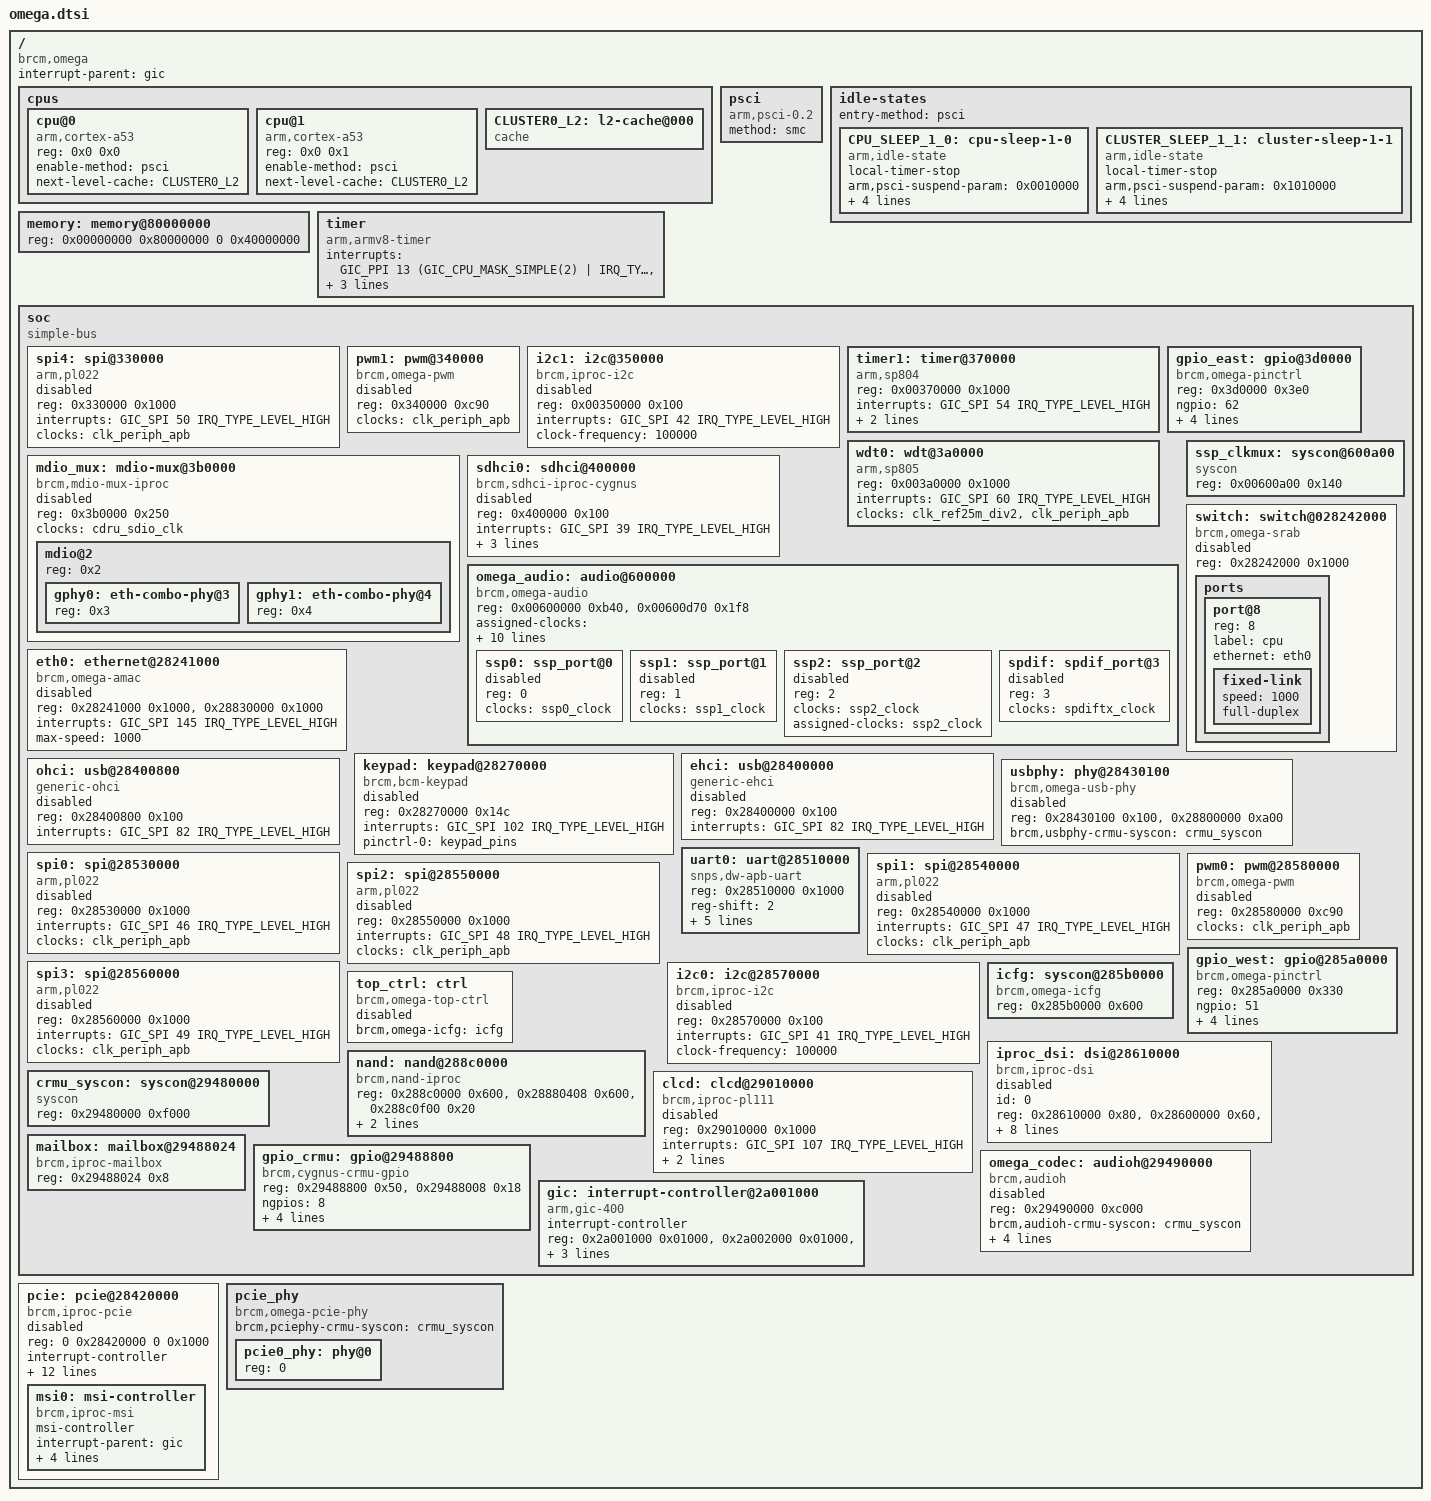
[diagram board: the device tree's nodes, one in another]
// SPDX-License-Identifier: (GPL-2.0 or BSD-3-Clause)
/*
 *  Copyright(c) 2018 Broadcom
 */

#include <dt-bindings/interrupt-controller/arm-gic.h>

/ {
	compatible = "brcm,omega";
	interrupt-parent = <&gic>;
	#address-cells = <2>;
	#size-cells = <2>;

	cpus {
		#address-cells = <2>;
		#size-cells = <0>;

		cpu@0 {
			device_type = "cpu";
			compatible = "arm,cortex-a53", "arm,armv8";
			reg = <0x0 0x0>;
			enable-method = "psci";
			next-level-cache = <&CLUSTER0_L2>;
		};

		cpu@1 {
			device_type = "cpu";
			compatible = "arm,cortex-a53", "arm,armv8";
			reg = <0x0 0x1>;
			enable-method = "psci";
			next-level-cache = <&CLUSTER0_L2>;
		};

		CLUSTER0_L2: l2-cache@000 {
			compatible = "cache";
		};

	};

	psci {
		compatible = "arm,psci-0.2";
		method = "smc";
	};

	idle-states {
		entry-method = "psci";
		CPU_SLEEP_1_0: cpu-sleep-1-0 {
			compatible = "arm,idle-state";
			local-timer-stop;
			arm,psci-suspend-param = <0x0010000>;
			entry-latency-us = <1>;
			exit-latency-us = <1>;
			min-residency-us = <900>;
			wakeup-latency-us = <1>;
		};

		CLUSTER_SLEEP_1_1: cluster-sleep-1-1 {
			compatible = "arm,idle-state";
			local-timer-stop;
			arm,psci-suspend-param = <0x1010000>;
			entry-latency-us = <1>;
			exit-latency-us = <1>;
			min-residency-us = <1800>;
			wakeup-latency-us = <1>;
		};
	};

	memory: memory@80000000 {
		device_type = "memory";
		reg = <0x00000000 0x80000000 0 0x40000000>;
	};

	timer {
		compatible = "arm,armv8-timer";
		interrupts = <GIC_PPI 13 (GIC_CPU_MASK_SIMPLE(2) |
			      IRQ_TYPE_LEVEL_LOW)>,
			     <GIC_PPI 14 (GIC_CPU_MASK_SIMPLE(2) |
			      IRQ_TYPE_LEVEL_LOW)>,
			     <GIC_PPI 11 (GIC_CPU_MASK_SIMPLE(2) |
			      IRQ_TYPE_LEVEL_LOW)>,
			     <GIC_PPI 10 (GIC_CPU_MASK_SIMPLE(2) |
			      IRQ_TYPE_LEVEL_LOW)>;
	};

	soc {
		compatible = "simple-bus";
		#address-cells = <1>;
		#size-cells = <1>;
		ranges = <0 0 0 0xffffffff>;

		#include "omega-clock.dtsi"
		#include "omega-pinctrl.dtsi"

		spi4: spi@330000 {
			compatible = "arm,pl022", "arm,primecell";
			reg = <0x330000 0x1000>;
			#address-cells = <1>;
			#size-cells = <0>;
			interrupts = <GIC_SPI 50 IRQ_TYPE_LEVEL_HIGH>;
			clocks = <&clk_periph_apb>;
			clock-names = "apb_pclk";
			status = "disabled";
		};

		pwm1: pwm@340000 {
			compatible = "brcm,omega-pwm";
			reg = <0x340000 0xc90>;
			clocks = <&clk_periph_apb>;
			#pwm-cells = <3>;
			status = "disabled";
		};

		i2c1: i2c@350000 {
			compatible = "brcm,iproc-i2c";
			reg = <0x00350000 0x100>;
			#address-cells = <1>;
			#size-cells = <0>;
			interrupts = <GIC_SPI 42 IRQ_TYPE_LEVEL_HIGH>;
			clock-frequency = <100000>;
			status = "disabled";
		};

		timer1: timer@370000 {
			compatible = "arm,sp804", "arm,primecell";
			reg = <0x00370000 0x1000>;
			interrupts = <GIC_SPI 54 IRQ_TYPE_LEVEL_HIGH>;
			clocks = <&clk_ref25m_div2>,
				 <&clk_ref25m_div2>,
				 <&clk_periph_apb>;
			clock-names = "timer1clk", "timer2clk", "apb_pclk";
		};

		wdt0: wdt@3a0000 {
			compatible = "arm,sp805", "arm,primecell";
			reg = <0x003a0000 0x1000>;
			interrupts = <GIC_SPI 60 IRQ_TYPE_LEVEL_HIGH>;
			clocks = <&clk_ref25m_div2>, <&clk_periph_apb>;
			clock-names = "wdogclk", "apb_pclk";
		};

		mdio_mux: mdio-mux@3b0000 {
			compatible = "brcm,mdio-mux-iproc";
			reg = <0x3b0000 0x250>;
			clocks = <&cdru_sdio_clk>;
			status = "disabled";
			#address-cells = <1>;
			#size-cells = <0>;

			mdio@2 {
				reg = <0x2>;
				#address-cells = <1>;
				#size-cells = <0>;

				gphy0: eth-combo-phy@3 {
					reg = <0x3>;
				};

				gphy1: eth-combo-phy@4 {
					reg = <0x4>;
				};
			};
		};

		gpio_east: gpio@3d0000 {
			compatible = "brcm,omega-pinctrl";
			reg = <0x3d0000 0x3e0>;
			ngpio = <62>;
			#gpio-cells = <2>;
			gpio-controller;
			interrupt-controller;
			#interrupt-cells = <3>;
			interrupts = <GIC_SPI 51 IRQ_TYPE_LEVEL_HIGH>;
			gpio-ranges = <&pinmux1 0 0 62>;
		};

		sdhci0: sdhci@400000 {
			compatible = "brcm,sdhci-iproc-cygnus";
			reg = <0x400000 0x100>;
			interrupts = <GIC_SPI 39 IRQ_TYPE_LEVEL_HIGH>;
			clocks = <&cdru_sdio_clk>;
			bus-width = <4>;
			sdhci,auto-cmd12;

			status = "disabled";
		};

		omega_audio: audio@600000 {
			compatible = "brcm,omega-audio";
			#address-cells = <1>;
			#size-cells = <0>;
			reg = <0x00600000 0xb40>, <0x00600d70 0x1f8>;
			reg-names = "aud", "i2s_in";

			assigned-clocks = <&audiopll_1 BCM_OMEGA_AUDIOPLL>,
					  <&ssp0_clock>,
					  <&ssp1_clock>,
					  <&ssp2_clock>,
					  <&spdiftx_clock>;
			assigned-clock-rates = <1376255989>;
			assigned-clock-parents = <0>,
					<&audiopll_1 BCM_OMEGA_AUDIOPLL_CH0>,
					<&audiopll_1 BCM_OMEGA_AUDIOPLL_CH1>,
					<&audiopll_1 BCM_OMEGA_AUDIOPLL_CH2>,
					<&audiopll_1 BCM_OMEGA_AUDIOPLL_CH3>;

			interrupts = <GIC_SPI 86 IRQ_TYPE_LEVEL_HIGH>; /* 143 */

			brcm,clk-mux-syscon = <&ssp_clkmux>;

			ssp0: ssp_port@0 {
				reg = <0>;
				clocks = <&ssp0_clock>;
				clock-names = "ssp_clk";
				status = "disabled";
			};

			ssp1: ssp_port@1 {
				reg = <1>;
				clocks = <&ssp1_clock>;
				clock-names = "ssp_clk";
				status = "disabled";
			};

			ssp2: ssp_port@2 {
				reg = <2>;
				clocks = <&ssp2_clock>;
				clock-names = "ssp_clk";
				assigned-clocks = <&ssp2_clock>;
				status = "disabled";
			};

			spdif: spdif_port@3 {
				reg = <3>;
				clocks = <&spdiftx_clock>;
				clock-names = "ssp_clk";
				status = "disabled";
			};
		};

		ssp_clkmux: syscon@600a00 {
			compatible = "syscon";
			reg = <0x00600a00 0x140>;
		};

		eth0: ethernet@28241000 {
			compatible = "brcm,omega-amac", "brcm,amac";
			reg = <0x28241000 0x1000>,
			      <0x28830000 0x1000>;
			reg-names = "amac_base",
				    "idm_base";
			interrupts = <GIC_SPI 145 IRQ_TYPE_LEVEL_HIGH>;
			max-speed = <1000>;
			status = "disabled";
		};

		switch: switch@028242000 {
			compatible = "brcm,omega-srab";
			reg = <0x28242000 0x1000>;
			status = "disabled";
			ports {
				#address-cells = <1>;
				#size-cells = <0>;
				port@8 {
					reg = <8>;
					label = "cpu";
					ethernet = <&eth0>;
					fixed-link {
						speed = <1000>;
						full-duplex;
					};
				};
			};
		};

		keypad: keypad@28270000 {
			compatible = "brcm,bcm-keypad";
			reg = <0x28270000 0x14c>;
			interrupts = <GIC_SPI 102 IRQ_TYPE_LEVEL_HIGH>;
			status = "disabled";
			pinctrl-names = "default";
			pinctrl-0 = <&keypad_pins>;
		};

		ehci: usb@28400000 {
			compatible = "generic-ehci";
			reg = <0x28400000 0x100>;
			interrupts = <GIC_SPI 82 IRQ_TYPE_LEVEL_HIGH>;
			status = "disabled";
		};

		ohci: usb@28400800 {
			compatible = "generic-ohci";
			reg = <0x28400800 0x100>;
			interrupts = <GIC_SPI 82 IRQ_TYPE_LEVEL_HIGH>;
			status = "disabled";
		};

		usbphy: phy@28430100 {
			compatible = "brcm,omega-usb-phy";
			reg = <0x28430100 0x100>,
			      <0x28800000 0xa00>;
			reg-names = "cdru-usbphy",
				    "usb2h-idm";
			#address-cells = <1>;
			#size-cells = <0>;

			brcm,usbphy-crmu-syscon = <&crmu_syscon>;
			status = "disabled";
		};

		uart0: uart@28510000 {
			device_type = "serial";
			compatible = "snps,dw-apb-uart";
			reg = <0x28510000 0x1000>;
			reg-shift = <2>;
			reg-io-width = <4>;
			clock-frequency = <25000000>;
			interrupt-parent = <&gic>;
			interrupts = <GIC_SPI 43 IRQ_TYPE_LEVEL_HIGH>;
			pinctrl-names = "default";
			pinctrl-0 = <&uart0_pins>;
		};

		spi0: spi@28530000 {
			compatible = "arm,pl022", "arm,primecell";
			reg = <0x28530000 0x1000>;
			#address-cells = <1>;
			#size-cells = <0>;
			interrupts = <GIC_SPI 46 IRQ_TYPE_LEVEL_HIGH>;
			clocks = <&clk_periph_apb>;
			clock-names = "apb_pclk";
			status = "disabled";
		};

		spi1: spi@28540000 {
			compatible = "arm,pl022", "arm,primecell";
			reg = <0x28540000 0x1000>;
			#address-cells = <1>;
			#size-cells = <0>;
			interrupts = <GIC_SPI 47 IRQ_TYPE_LEVEL_HIGH>;
			clocks = <&clk_periph_apb>;
			clock-names = "apb_pclk";
			status = "disabled";
		};

		spi2: spi@28550000 {
			compatible = "arm,pl022", "arm,primecell";
			reg = <0x28550000 0x1000>;
			#address-cells = <1>;
			#size-cells = <0>;
			interrupts = <GIC_SPI 48 IRQ_TYPE_LEVEL_HIGH>;
			clocks = <&clk_periph_apb>;
			clock-names = "apb_pclk";
			status = "disabled";
		};

		spi3: spi@28560000 {
			compatible = "arm,pl022", "arm,primecell";
			reg = <0x28560000 0x1000>;
			#address-cells = <1>;
			#size-cells = <0>;
			interrupts = <GIC_SPI 49 IRQ_TYPE_LEVEL_HIGH>;
			clocks = <&clk_periph_apb>;
			clock-names = "apb_pclk";
			status = "disabled";
		};

		i2c0: i2c@28570000 {
			compatible = "brcm,iproc-i2c";
			reg = <0x28570000 0x100>;
			#address-cells = <1>;
			#size-cells = <0>;
			interrupts = <GIC_SPI 41 IRQ_TYPE_LEVEL_HIGH>;
			clock-frequency = <100000>;
			status = "disabled";
		};

		pwm0: pwm@28580000 {
			compatible = "brcm,omega-pwm";
			reg = <0x28580000 0xc90>;
			clocks = <&clk_periph_apb>;
			#pwm-cells = <3>;
			status = "disabled";
		};

		gpio_west: gpio@285a0000 {
			compatible = "brcm,omega-pinctrl";
			reg = <0x285a0000 0x330>;
			ngpio = <51>;
			#gpio-cells = <2>;
			gpio-controller;
			interrupt-controller;
			#interrupt-cells = <3>;
			interrupts = <GIC_SPI 52 IRQ_TYPE_LEVEL_HIGH>;
			gpio-ranges = <&pinmux0 0 0 51>;
		};

		icfg: syscon@285b0000 {
			compatible = "brcm,omega-icfg", "syscon";
			reg = <0x285b0000 0x600>;
		};

		top_ctrl: ctrl {
			compatible = "brcm,omega-top-ctrl";
			brcm,omega-icfg = <&icfg>;
			status = "disabled";
		};

		iproc_dsi: dsi@28610000 {
			compatible = "brcm,iproc-dsi";
			id = <0>;
			reg-names = "dsi-phy", "axipv", "pv", "gen-pll";
			reg = <0x28610000 0x80>,
				<0x28600000 0x60>,
				<0x28600400 0x40>,
				<0x28600800 0x50>;
			interrupts = <GIC_SPI 108 IRQ_TYPE_LEVEL_HIGH>,
					<GIC_SPI 110 IRQ_TYPE_LEVEL_HIGH>,
					<GIC_SPI 109 IRQ_TYPE_LEVEL_HIGH>;
			assigned-clocks = <&audiopll_0 BCM_OMEGA_AUDIOPLL>;
			assigned-clock-rates = <1171497600>;
			clocks = <&audiopll_0 BCM_OMEGA_AUDIOPLL_CH3>;
			clock-names = "mipidsi_clk";
			brcm,num-fb = <3>;
			status = "disabled";
		};

		nand: nand@288c0000 {
			compatible = "brcm,nand-iproc", "brcm,brcmnand-v6.1";
			reg = <0x288c0000 0x600>,
			      <0x28880408 0x600>,
			      <0x288c0f00 0x20>;
			reg-names = "nand", "iproc-idm", "iproc-ext";
			interrupts = <GIC_SPI 40 IRQ_TYPE_LEVEL_HIGH>;
			#address-cells = <1>;
			#size-cells = <0>;
			brcm,nand-has-wp;
		};

		clcd: clcd@29010000 {
			compatible = "brcm,iproc-pl111", "arm,primecell";
			reg = <0x29010000 0x1000>;
			interrupts = <GIC_SPI 107 IRQ_TYPE_LEVEL_HIGH>;
			interrupt-names = "combined";
			clocks = <&cdru_video_axi_clock>, <&clk_periph_apb>;
			clock-names = "clcdclk", "apb_pclk";
			clcd-enable-clock-divisor;
			status = "disabled";
		};

		crmu_syscon: syscon@29480000 {
			compatible = "syscon";
			reg = <0x29480000 0xf000>;
		};

		mailbox: mailbox@29488024 {
			compatible = "brcm,iproc-mailbox";
			reg = <0x29488024 0x8>;
			#mbox-cells = <1>;
		};

		gpio_crmu: gpio@29488800 {
			compatible = "brcm,cygnus-crmu-gpio";
			reg = <0x29488800 0x50>,
			      <0x29488008 0x18>;
			ngpios = <8>;
			#gpio-cells = <2>;
			gpio-controller;
			interrupt-controller;
			interrupts = <GIC_SPI 192 IRQ_TYPE_LEVEL_HIGH>;
			mboxes = <&mailbox 0>;
		};

		omega_codec: audioh@29490000 {
			#sound-dai-cells = <1>;
			compatible = "brcm,audioh";
			reg = <0x29490000 0xc000>;
			reg-names = "audioh";

			brcm,audioh-crmu-syscon = <&crmu_syscon>;
			interrupts = <GIC_SPI 175 IRQ_TYPE_LEVEL_HIGH>;

			clocks = <&codec_clock>;
			clock-names = "codec_clk";

			assigned-clocks = <&codec_clock>;
			assigned-clock-parents = <&genpll0_26m>;

			status = "disabled";
		};

		gic: interrupt-controller@2a001000 {
			compatible = "arm,gic-400";
			#interrupt-cells = <3>;
			#address-cells = <1>;
			#size-cells = <1>;
			ranges;
			interrupt-controller;
			reg = <0x2a001000 0x01000>,
			      <0x2a002000 0x01000>,
			      <0x2a004000 0x02000>,
			      <0x2a006000 0x01000>;
			interrupts = <GIC_PPI 9 (GIC_CPU_MASK_SIMPLE(2) |
			IRQ_TYPE_LEVEL_HIGH)>;
		};
	};

	pcie: pcie@28420000 {
		compatible = "brcm,iproc-pcie";
		reg = <0 0x28420000 0 0x1000>;
		interrupt-controller;
		#interrupt-cells = <1>;
		interrupt-map-mask = <0 0 0 7>;
		interrupt-map = <0 0 0 1 &pcie 1>,
				<0 0 0 2 &pcie 2>,
				<0 0 0 3 &pcie 3>,
				<0 0 0 4 &pcie 4>;
		interrupts = <GIC_SPI 16 IRQ_TYPE_LEVEL_HIGH>;
		linux,pci-domain = <0>;
		bus-range = <0x00 0xff>;
		#address-cells = <3>;
		#size-cells = <2>;
		device_type = "pci";
		status = "disabled";

		ranges = <0x83000000 0 0x40000000 0 0x40000000 0 0x08000000>;
		brcm,pcie-ob;
		brcm,pcie-ob-axi-offset = <0x00000000>;

		dma-ranges = <0x43000000 0 0x80000000 0 0x80000000 0 0x80000000>;

		phys = <&pcie0_phy>;
		phy-names = "pcie-phy";

		msi-parent = <&msi0>;
		msi0: msi-controller {
			compatible = "brcm,iproc-msi";
			msi-controller;
			interrupt-parent = <&gic>;
			interrupts = <GIC_SPI 12 IRQ_TYPE_LEVEL_HIGH>,
				     <GIC_SPI 13 IRQ_TYPE_LEVEL_HIGH>,
				     <GIC_SPI 14 IRQ_TYPE_LEVEL_HIGH>,
				     <GIC_SPI 15 IRQ_TYPE_LEVEL_HIGH>;
		};
	};

	pcie_phy: pcie_phy {
		compatible = "brcm,omega-pcie-phy";
		#address-cells = <1>;
		#size-cells = <0>;

		brcm,pciephy-crmu-syscon = <&crmu_syscon>;

		pcie0_phy: phy@0 {
			reg = <0>;
			#phy-cells = <0>;
		};
	};

	#include "omega-optee.dtsi"
};
